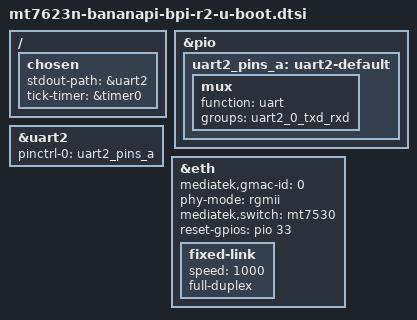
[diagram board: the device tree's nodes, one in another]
// SPDX-License-Identifier: GPL-2.0
/*
 * Author: Frank Wunderlich <frank-w@public-files.de>
 */

#include "mt7623n-u-boot.dtsi"

/{
	chosen {
		stdout-path = &uart2;
		tick-timer = &timer0;
	};
};

&pio {
	uart2_pins_a: uart2-default {
		mux {
			function = "uart";
			groups =  "uart2_0_txd_rxd";
		};
	};
};

&uart2 {
	pinctrl-names = "default";
	pinctrl-0 = <&uart2_pins_a>;
	status = "okay";
};

&eth {
	status = "okay";
	mediatek,gmac-id = <0>;
	phy-mode = "rgmii";
	mediatek,switch = "mt7530";
	reset-gpios = <&pio 33 GPIO_ACTIVE_HIGH>;

	fixed-link {
		speed = <1000>;
		full-duplex;
	};
};
